# TM4C1294NCPDT register map
Vendor: Texas Instruments; File version: 2.2.0.295
TM4C1294NCPDT Cortex-M4F microcontroller
CPU: CM4 r0p1, little endian, MPU, FPU, 3 interrupt priority bits
Registers are 32-bit, read-write, no defined reset value unless marked. A register's access mark holds for its fields unless they carry their own. Offsets are from the block's base; lines under a group give offsets from that group; [hi:lo] are bit positions; {n}, {i} and the like mark numbered series; 'fields as' and 'values as' point back to an identical list; <NAME> marks a mode.

## Memory map
0x40000000 WATCHDOG0 — Watchdog Timer (WATCHDOG0)
0x40001000 WATCHDOG1 — Watchdog Timer (WATCHDOG1)
0x40008000 SSI0 — SSI (SSI0)
0x40009000 SSI1 — SSI (SSI1)
0x4000A000 SSI2 — SSI (SSI2)
0x4000B000 SSI3 — SSI (SSI3)
{0x4000C000+0x1000*n} UART{n} (n=0..7) — UART (UART{n})
0x40020000 I2C0 — I2C (I2C0)
0x40021000 I2C1 — I2C (I2C1)
0x40022000 I2C2 — I2C (I2C2)
0x40023000 I2C3 — I2C (I2C3)
0x40028000 PWM0 — PWM (PWM0)
0x4002C000 QEI0 — QEI (QEI0)
0x40030000 TIMER0 — Timer (TIMER0)
0x40031000 TIMER1 — Timer (TIMER1)
0x40032000 TIMER2 — Timer (TIMER2)
0x40033000 TIMER3 — Timer (TIMER3)
0x40034000 TIMER4 — Timer (TIMER4)
0x40035000 TIMER5 — Timer (TIMER5)
0x40038000 ADC0 — ADC (ADC0)
0x40039000 ADC1 — ADC (ADC1)
0x4003C000 COMP — Comparator (COMP)
0x40040000 CAN0 — CAN (CAN0)
0x40041000 CAN1 — CAN (CAN1)
0x40050000 USB0 — Univeral Serial Bus (USB0)
0x40058000 GPIO_PORTA_AHB
0x40059000 GPIO_PORTB_AHB
0x4005A000 GPIO_PORTC_AHB
0x4005B000 GPIO_PORTD_AHB
0x4005C000 GPIO_PORTE_AHB
0x4005D000 GPIO_PORTF_AHB
0x4005E000 GPIO_PORTG_AHB
0x4005F000 GPIO_PORTH_AHB
0x40060000 GPIO_PORTJ_AHB
0x40061000 GPIO_PORTK
0x40062000 GPIO_PORTL
0x40063000 GPIO_PORTM
0x40064000 GPIO_PORTN
0x40065000 GPIO_PORTP
0x40066000 GPIO_PORTQ
0x400AF000 EEPROM — EEPROM (EEPROM)
0x400B8000 I2C8 — I2C (I2C8)
0x400B9000 I2C9 — I2C (I2C9)
0x400C0000 I2C4 — I2C (I2C4)
0x400C1000 I2C5 — I2C (I2C5)
0x400C2000 I2C6 — I2C (I2C6)
0x400C3000 I2C7 — I2C (I2C7)
0x400D0000 EPI0 — External Peripheral Interface (EPI0)
0x400E0000 TIMER6 — Timer (TIMER6)
0x400E1000 TIMER7 — Timer (TIMER7)
0x400EC000 EMAC0 — EMAC (EMAC0)
0x400F9000 SYSEXC — System Exception Module (SYSEXC)
0x400FC000 HIB — Hibernation module (HIB)
0x400FD000 FLASH — FLASH (FLASH CTRL)
0x400FE000 SYSCTL — System Control (SYSCTL)
0x400FF000 UDMA — Micro Direct Memory Access (UDMA)
0x44030000 CCM0 — EC (CCM0)
0xE000E000 NVIC — NVIC (NVIC)

## WATCHDOG0 — Watchdog Timer (WATCHDOG0)
Base 0x40000000
Same registers: WATCHDOG1 0x40001000
0x00 LOAD
  [31:0] VALUE — Watchdog Load Value
0x04 VALUE
  [31:0] VALUE — Watchdog Value
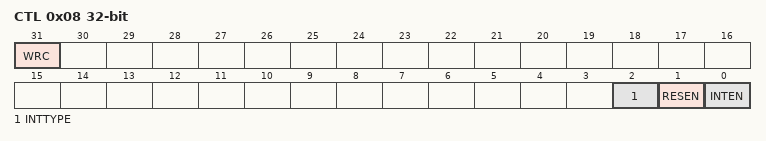
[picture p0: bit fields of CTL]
0x08 CTL
  [31] WRC — Write Complete
  [2] INTTYPE — Watchdog Interrupt Type
  [1] RESEN — Watchdog Reset Enable
  [0] INTEN — Watchdog Interrupt Enable
0x0C ICR
  [31:0] VALUE — Watchdog Interrupt Clear
0x10 RIS
  [0] WDTRIS — Watchdog Raw Interrupt Status
0x14 MIS
  [0] WDTMIS — Watchdog Masked Interrupt Status
0x418 TEST
  [8] STALL — Watchdog Stall Enable
0xC00 LOCK
  [31:0] VALUE — Watchdog Lock
  [0] LOCKED

## SSI0 — SSI (SSI0)
Base 0x40008000
Same registers: SSI1 0x40009000, SSI2 0x4000A000, SSI3 0x4000B000
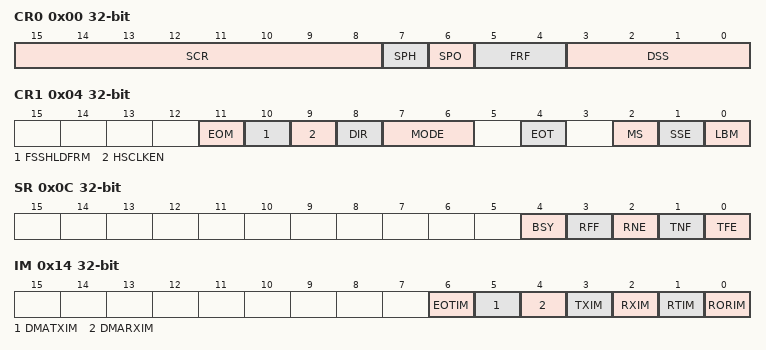
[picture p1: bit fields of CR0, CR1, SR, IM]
0x00 CR0
  [15:8] SCR — SSI Serial Clock Rate
  [7] SPH — SSI Serial Clock Phase
  [6] SPO — SSI Serial Clock Polarity
  [5:4] FRF — SSI Frame Format Select
    0=MOTO (Freescale SPI Frame Format); 1=TI (Synchronous Serial Frame Format)
  [3:0] DSS — SSI Data Size Select
    {v}={v+1}-bit data (v=3..15)
0x04 CR1
  [11] EOM — Stop Frame (End of Message)
  [10] FSSHLDFRM — FSS Hold Frame
  [9] HSCLKEN — High Speed Clock Enable
  [8] DIR — SSI Direction of Operation
  [7:6] MODE — SSI Mode
    0=LEGACY (Legacy SSI mode); 1=BI (Bi-SSI mode); 2=QUAD (Quad-SSI Mode); 3=ADVANCED (Advanced SSI Mode with 8-bit)
  [4] EOT — End of Transmission
  [2] MS — SSI Master/Slave Select
  [1] SSE — SSI Synchronous Serial Port
  [0] LBM — SSI Loopback Mode
0x08 DR read-modifies
  [15:0] DATA — SSI Receive/Transmit Data
0x0C SR
  [4] BSY — SSI Busy Bit
  [3] RFF — SSI Receive FIFO Full
  [2] RNE — SSI Receive FIFO Not Empty
  [1] TNF — SSI Transmit FIFO Not Full
  [0] TFE — SSI Transmit FIFO Empty
0x10 CPSR
  [7:0] CPSDVSR — SSI Clock Prescale Divisor
0x14 IM
  [6] EOTIM — End of Transmit Interrupt Mask
  [5] DMATXIM — SSI Transmit DMA Interrupt Mask
  [4] DMARXIM — SSI Receive DMA Interrupt Mask
  [3] TXIM — SSI Transmit FIFO Interrupt Mask
  [2] RXIM — SSI Receive FIFO Interrupt Mask
  [1] RTIM — SSI Receive Time-Out Interrupt
  [0] RORIM — SSI Receive Overrun Interrupt
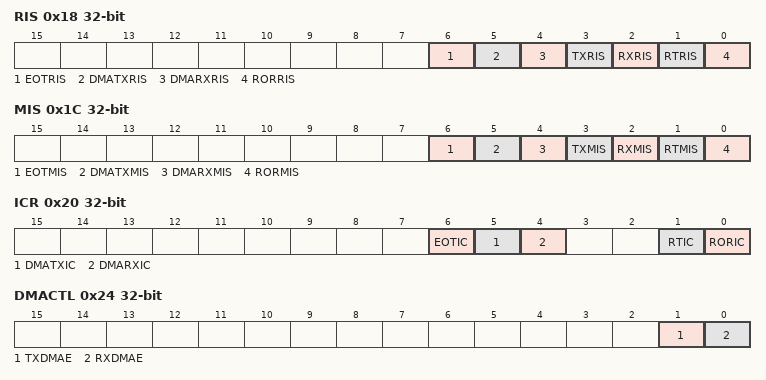
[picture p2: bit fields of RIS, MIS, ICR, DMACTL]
0x18 RIS
  [6] EOTRIS — End of Transmit Raw Interrupt
  [5] DMATXRIS — SSI Transmit DMA Raw Interrupt
  [4] DMARXRIS — SSI Receive DMA Raw Interrupt
  [3] TXRIS — SSI Transmit FIFO Raw Interrupt
  [2] RXRIS — SSI Receive FIFO Raw Interrupt
  [1] RTRIS — SSI Receive Time-Out Raw
  [0] RORRIS — SSI Receive Overrun Raw
0x1C MIS
  [6] EOTMIS — End of Transmit Masked Interrupt
  [5] DMATXMIS — SSI Transmit DMA Masked
  [4] DMARXMIS — SSI Receive DMA Masked Interrupt
  [3] TXMIS — SSI Transmit FIFO Masked
  [2] RXMIS — SSI Receive FIFO Masked
  [1] RTMIS — SSI Receive Time-Out Masked
  [0] RORMIS — SSI Receive Overrun Masked
0x20 ICR
  [6] EOTIC — End of Transmit Interrupt Clear
  [5] DMATXIC — SSI Transmit DMA Interrupt Clear
  [4] DMARXIC — SSI Receive DMA Interrupt Clear
  [1] RTIC — SSI Receive Time-Out Interrupt
  [0] RORIC — SSI Receive Overrun Interrupt
0x24 DMACTL
  [1] TXDMAE — Transmit DMA Enable
  [0] RXDMAE — Receive DMA Enable
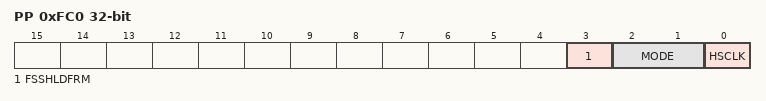
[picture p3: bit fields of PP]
0xFC0 PP
  [3] FSSHLDFRM — FSS Hold Frame Capability
  [2:1] MODE — Mode of Operation
    0=LEGACY (Legacy SSI mode); 1=ADVBI (Legacy mode, Advanced SSI mode); 2=ADVBIQUAD (Legacy mode, Advanced mode,)
  [0] HSCLK — High Speed Capability
0xFC8 CC
  [3:0] CS — SSI Baud Clock Source
    0=SYSPLL (System clock (based on clock); 5=PIOSC

## Notices in the file
(TivaWare for C Series 2.2.0.295, BSD license in TI-BSD-EULA.txt). Do not edit.
